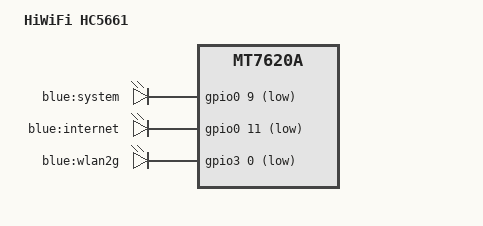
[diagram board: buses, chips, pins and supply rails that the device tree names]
#include "mt7620a_hiwifi_hc5x61.dtsi"

/ {
	compatible = "hiwifi,hc5661", "hiwifi,hc5x61", "ralink,mt7620a-soc";
	model = "HiWiFi HC5661";

	aliases {
		led-boot = &led_system;
		led-failsafe = &led_system;
		led-running = &led_system;
		led-upgrade = &led_system;
	};

	leds {
		compatible = "gpio-leds";

		led_system: system {
			label = "blue:system";
			gpios = <&gpio0 9 GPIO_ACTIVE_LOW>;
		};

		internet {
			label = "blue:internet";
			gpios = <&gpio0 11 GPIO_ACTIVE_LOW>;
		};

		wlan2g {
			label = "blue:wlan2g";
			gpios = <&gpio3 0 GPIO_ACTIVE_LOW>;
			linux,default-trigger = "phy0tpt";
		};
	};
};
